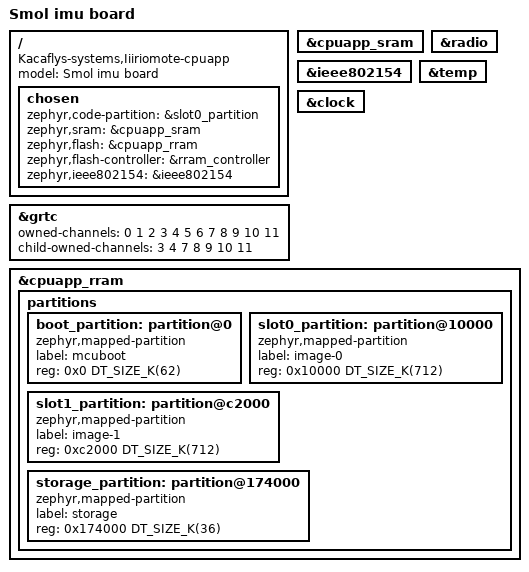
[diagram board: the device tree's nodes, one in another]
/dts-v1/;

#include <nordic/nrf54l15_cpuapp.dtsi>
#include "Iiiriomote-pinctrl.dtsi"

/ {
	model = "Smol imu board";
	compatible = "Kacaflys-systems,Iiiriomote-cpuapp";

	chosen {
		zephyr,code-partition = &slot0_partition;
		zephyr,sram = &cpuapp_sram;
		zephyr,flash = &cpuapp_rram;
		zephyr,flash-controller = &rram_controller;
		zephyr,ieee802154 = &ieee802154;
	};

};

&grtc {
	owned-channels = <0 1 2 3 4 5 6 7 8 9 10 11>;
	/* Channels 7-11 reserved for Zero Latency IRQs, 3-4 for FLPR */
	child-owned-channels = <3 4 7 8 9 10 11>;
	status = "okay";
};

&cpuapp_sram {
	status = "okay";
};

&radio {
	status = "okay";
};

&ieee802154 {
	status = "okay";
};

&temp {
	status = "okay";
};

&clock {
	status = "okay";
};

/* These partition sizes assume no FLPR area in RRAM */
&cpuapp_rram {
	partitions {
		#address-cells = <1>;
		#size-cells = <1>;
		ranges;

		boot_partition: partition@0 {
			compatible = "zephyr,mapped-partition";
			label = "mcuboot";
			/*
			 * MCUBoot partition is set to 62k to allow FPROTECT to be enabled by
			 * default.
                         */
			reg = <0x0 DT_SIZE_K(62)>;
		};

		slot0_partition: partition@10000 {
			compatible = "zephyr,mapped-partition";
			label = "image-0";
			reg = <0x10000 DT_SIZE_K(712)>;
		};

		slot1_partition: partition@c2000 {
			compatible = "zephyr,mapped-partition";
			label = "image-1";
			reg = <0xc2000 DT_SIZE_K(712)>;
		};

		storage_partition: partition@174000 {
			compatible = "zephyr,mapped-partition";
			label = "storage";
			reg = <0x174000 DT_SIZE_K(36)>;
		};
	};
};
